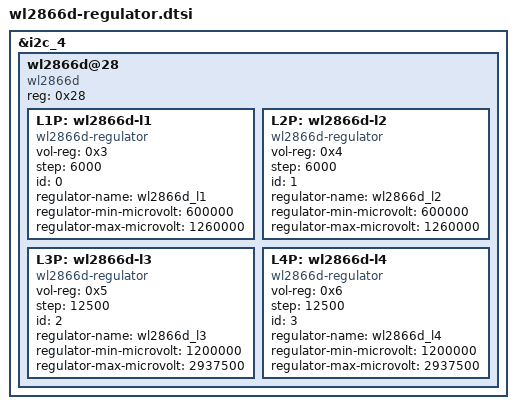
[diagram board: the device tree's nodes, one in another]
// SPDX-License-Identifier: GPL-2.0+
&i2c_4 {
	wl2866d@28 {
		compatible = "wl2866d";
		#address-cells = <1>;
		#size-cells = <0>;
		reg = <0x28>;
		L1P: wl2866d-l1 {
			compatible = "wl2866d-regulator";
			#address-cells = <1>;
			#size-cells = <0>;
			vol-reg = <0x3>;
			step = <6000>;
			id = <0>;
			regulator-name = "wl2866d_l1";
			regulator-min-microvolt = <600000>;
			regulator-max-microvolt = <1260000>;
		};
		L2P: wl2866d-l2 {
			compatible = "wl2866d-regulator";
			#address-cells = <1>;
			#size-cells = <0>;
			vol-reg = <0x4>;
			step = <6000>;
			id = <1>;
			regulator-name = "wl2866d_l2";
			regulator-min-microvolt = <600000>;
			regulator-max-microvolt = <1260000>;
		};
		L3P: wl2866d-l3 {
			compatible = "wl2866d-regulator";
			#address-cells = <1>;
			#size-cells = <0>;
			vol-reg = <0x5>;
			step = <12500>;
			id = <2>;
			regulator-name = "wl2866d_l3";
			regulator-min-microvolt = <1200000>;
			regulator-max-microvolt = <2937500>;
		};
		L4P: wl2866d-l4 {
			compatible = "wl2866d-regulator";
			#address-cells = <1>;
			#size-cells = <0>;
			vol-reg = <0x6>;
			step = <12500>;
			id = <3>;
			regulator-name = "wl2866d_l4";
			regulator-min-microvolt = <1200000>;
			regulator-max-microvolt = <2937500>;
		};
	};
};
